# ATtiny3227 register map
Vendor: Atmel; File version: 1.0
CPU: other r0p0, little endian, no MPU, no FPU, 4 interrupt priority bits
Registers are 8-bit, read-write, reset 0x0 unless marked. A register's access mark holds for its fields unless they carry their own. Offsets are from the block's base; [hi:lo] are bit positions.

## PORTMUX — Port Multiplexer
Base 0x008005E0
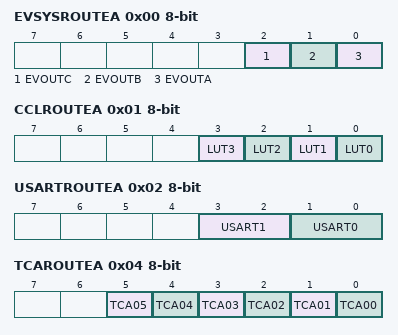
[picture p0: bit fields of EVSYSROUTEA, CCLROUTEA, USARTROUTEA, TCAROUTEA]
0x00 EVSYSROUTEA — Port Multiplexer EVSYS
  [2] EVOUTC — Event Output C
    0=DEFAULT (EVOUTC: PC2)
  [1] EVOUTB — Event Output B
    0=DEFAULT (EVOUTB: PB2); 1=ALT1 (EVOUTB: PB7)
  [0] EVOUTA — Event Output A
    0=DEFAULT (EVOUTA: PA2); 1=ALT1 (EVOUTA: PA7)
0x01 CCLROUTEA — Port Multiplexer CCL
  [3] LUT3 — CCL LUT3
    0=DEFAULT (INn: PC0, PC1, PC2. OUT: PC4.); 1=ALT1 (INn: PC0, PC1, PC2. OUT: PA5.)
  [2] LUT2 — CCL LUT2
    0=DEFAULT (INn: PB0, PB1, PB2. OUT: PB3.); 1=ALT1 (INn: PB0, PB1, PB2. OUT: PB6.)
  [1] LUT1 — CCL LUT1
    0=DEFAULT (INn: PC3, PC4, PC5. OUT: PA7.); 1=ALT1 (INn: PC3, PC4, PC5. OUT: PC1.)
  [0] LUT0 — CCL LUT0
    0=DEFAULT (INn: PA0, PA1, PA2. OUT: PA4.); 1=ALT1 (INn: PA0, PA1, PA2. OUT: PB4.)
0x02 USARTROUTEA — Port Multiplexer USART register A
  [3:2] USART1 — Port Multiplexer USART1
    0=DEFAULT (TxD: PA1, RxD: PA2, XCK: PA3, XDIR: PA4); 1=ALT1 (TxD: PC2, RxD: PC1, XCK: PC0, XDIR: PC3); 3=NONE (Not connected to any pins)
  [1:0] USART0 — Port Multiplexer USART0
    0=DEFAULT (TxD: PB2, RxD: PB3, XCK: PB1, XDIR: PB0); 1=ALT1 (TxD: PA1, RxD: PA2, XCK: PA3, XDIR: PA4); 3=NONE (Not connected to any pins)
0x03 SPIROUTEA — Port Multiplexer TWI and SPI
  [1:0] SPI0 — Port Multiplexer SPI0
    0=DEFAULT (MOSI: PA1, MISO: PA2, SCK: PA3, SS: PA4); 1=ALT1 (MOSI: PC2, MISO: PC1, SCK: PC0, SS: PC3); 3=NONE (Not connected to any pins)
0x04 TCAROUTEA — Port Multiplexer TCA
  [5] TCA05 — Port Multiplexer TCA0 Output 5
    0=DEFAULT (WO5: PA5); 1=ALT1 (WO5: PC5)
  [4] TCA04 — Port Multiplexer TCA0 Output 4
    0=DEFAULT (WO4: PA4); 1=ALT1 (WO4: PC4)
  [3] TCA03 — Port Multiplexer TCA0 Output 3
    0=DEFAULT (WO3: PA3); 1=ALT1 (WO3: PC3)
  [2] TCA02 — Port Multiplexer TCA0 Output 2
    0=DEFAULT (WO2: PB2); 1=ALT1 (WO2: PB5)
  [1] TCA01 — Port Multiplexer TCA0 Output 1
    0=DEFAULT (WO1: PB1); 1=ALT1 (WO1: PB4)
  [0] TCA00 — Port Multiplexer TCA0 Output 0
    0=DEFAULT (WO0: PB0); 1=ALT1 (WO0: PB3)
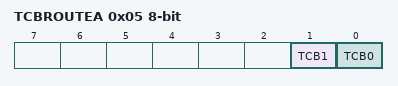
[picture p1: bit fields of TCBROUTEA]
0x05 TCBROUTEA — Port Multiplexer TCB
  [1] TCB1 — Port Multiplexer TCB1
    0=DEFAULT (WO: PA3); 1=ALT1 (WO: PC4)
  [0] TCB0 — Port Multiplexer TCB0
    0=DEFAULT (WO: PA5); 1=ALT1 (WO: PC0)

## RSTCTRL — Reset controller
Base 0x00800040
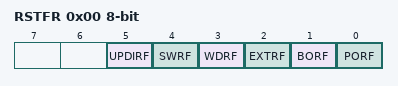
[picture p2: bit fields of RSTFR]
0x00 RSTFR — Reset Flags
  [5] UPDIRF — UPDI Reset flag
  [4] SWRF — Software Reset flag
  [3] WDRF — Watch dog Reset flag
  [2] EXTRF — External Reset flag
  [1] BORF — Brown out detector Reset flag
  [0] PORF — Power on Reset flag
0x01 SWRR — Software Reset
  [0] SWRE — Software reset enable

## RTC — Real-Time Counter
Base 0x00800140
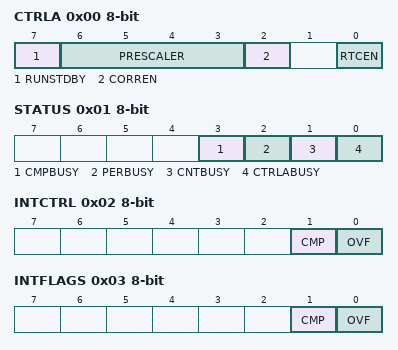
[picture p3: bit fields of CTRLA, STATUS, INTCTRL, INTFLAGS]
0x00 CTRLA — Control A
  [7] RUNSTDBY — Run In Standby
  [6:3] PRESCALER — Prescaling Factor
    0=DIV1 (RTC Clock / 1); 1=DIV2 (RTC Clock / 2); 2=DIV4 (RTC Clock / 4); 3=DIV8 (RTC Clock / 8); 4=DIV16 (RTC Clock / 16); 5=DIV32 (RTC Clock / 32); 6=DIV64 (RTC Clock / 64); 7=DIV128 (RTC Clock / 128); 8=DIV256 (RTC Clock / 256); 9=DIV512 (RTC Clock / 512); 10=DIV1024 (RTC Clock / 1024); 11=DIV2048 (RTC Clock / 2048); 12=DIV4096 (RTC Clock / 4096); 13=DIV8192 (RTC Clock / 8192); 14=DIV16384 (RTC Clock / 16384); 15=DIV32768 (RTC Clock / 32768)
  [2] CORREN — Correction enable
  [0] RTCEN — Enable
0x01 STATUS ro
  [3] CMPBUSY — Comparator Synchronization Busy Flag
  [2] PERBUSY — Period Synchronization Busy Flag
  [1] CNTBUSY — Count Synchronization Busy Flag
  [0] CTRLABUSY — CTRLA Synchronization Busy Flag
0x02 INTCTRL — Interrupt Control
  [1] CMP — Compare Match Interrupt enable
  [0] OVF — Overflow Interrupt enable
0x03 INTFLAGS — Interrupt Flags
  [1] CMP — Compare Match Interrupt
  [0] OVF — Overflow Interrupt Flag
0x04 TEMP — Temporary
0x05 DBGCTRL — Debug control
  [0] DBGRUN — Run in debug
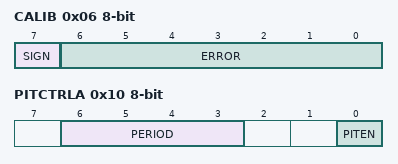
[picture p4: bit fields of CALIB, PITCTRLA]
0x06 CALIB — Calibration
  [7] SIGN — Error Correction Sign Bit
  [6:0] ERROR — Error Correction Value
0x07 CLKSEL — Clock Select
  [1:0] CLKSEL
    0=INT32K (Internal 32kHz OSC); 1=INT1K (Internal 1kHz OSC); 2=TOSC32K (32KHz Crystal OSC); 3=EXTCLK (External Clock)
0x08 CNT 16-bit (reset mask 0xFF) — Counter
0x0A PER 16-bit (reset mask 0xFF) — Period
0x0C CMP 16-bit (reset mask 0xFF) — Compare
0x10 PITCTRLA — PIT Control A
  [6:3] PERIOD
    0=OFF; 1=CYC4 (RTC Clock Cycles 4); 2=CYC8 (RTC Clock Cycles 8); 3=CYC16 (RTC Clock Cycles 16); 4=CYC32 (RTC Clock Cycles 32); 5=CYC64 (RTC Clock Cycles 64); 6=CYC128 (RTC Clock Cycles 128); 7=CYC256 (RTC Clock Cycles 256); 8=CYC512 (RTC Clock Cycles 512); 9=CYC1024 (RTC Clock Cycles 1024); 10=CYC2048 (RTC Clock Cycles 2048); 11=CYC4096 (RTC Clock Cycles 4096); 12=CYC8192 (RTC Clock Cycles 8192); 13=CYC16384 (RTC Clock Cycles 16384); 14=CYC32768 (RTC Clock Cycles 32768)
  [0] PITEN — Enable
0x11 PITSTATUS ro
  [0] CTRLBUSY — CTRLA Synchronization Busy Flag
0x12 PITINTCTRL — PIT Interrupt Control
  [0] PI — Periodic Interrupt
0x13 PITINTFLAGS — PIT Interrupt Flags
  [0] PI — Periodic Interrupt
0x15 PITDBGCTRL — PIT Debug control
  [0] DBGRUN — Run in debug
